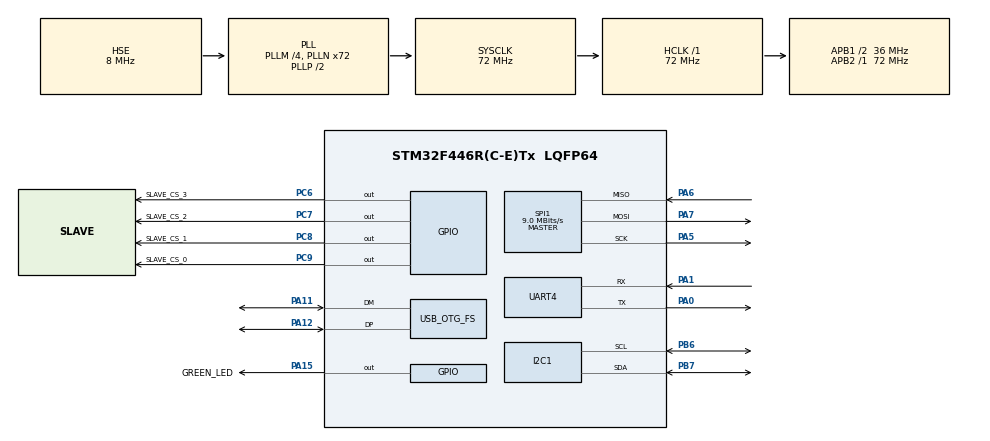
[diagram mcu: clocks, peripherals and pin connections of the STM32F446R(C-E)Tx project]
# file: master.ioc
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Dma.Request0=SPI1_RX
Dma.Request1=SPI1_TX
Dma.SPI1_RX.0.Direction=DMA_PERIPH_TO_MEMORY
Dma.SPI1_RX.0.FIFOMode=DMA_FIFOMODE_DISABLE
Dma.SPI1_RX.0.Instance=DMA2_Stream0
Dma.SPI1_RX.0.MemDataAlignment=DMA_MDATAALIGN_BYTE
Dma.SPI1_RX.0.MemInc=DMA_MINC_ENABLE
Dma.SPI1_RX.0.Mode=DMA_NORMAL
Dma.SPI1_RX.0.PeriphDataAlignment=DMA_PDATAALIGN_BYTE
Dma.SPI1_RX.0.PeriphInc=DMA_PINC_DISABLE
Dma.SPI1_RX.0.Priority=DMA_PRIORITY_LOW
Dma.SPI1_TX.1.Direction=DMA_MEMORY_TO_PERIPH
Dma.SPI1_TX.1.FIFOMode=DMA_FIFOMODE_DISABLE
Dma.SPI1_TX.1.Instance=DMA2_Stream3
Dma.SPI1_TX.1.MemDataAlignment=DMA_MDATAALIGN_BYTE
Dma.SPI1_TX.1.MemInc=DMA_MINC_ENABLE
Dma.SPI1_TX.1.Mode=DMA_NORMAL
Dma.SPI1_TX.1.PeriphDataAlignment=DMA_PDATAALIGN_BYTE
Dma.SPI1_TX.1.PeriphInc=DMA_PINC_DISABLE
Dma.SPI1_TX.1.Priority=DMA_PRIORITY_LOW
I2C1.I2C_Mode=I2C_Fast
Mcu.Family=STM32F4
Mcu.Name=STM32F446R(C-E)Tx
Mcu.Package=LQFP64
NVIC.DMA2_Stream0_IRQn=true\:0\:0\:false\:false\:true\:false\:true\:true
NVIC.DMA2_Stream3_IRQn=true\:0\:0\:false\:false\:true\:false\:true\:true
NVIC.I2C1_EV_IRQn=true\:0\:0\:false\:false\:true\:true\:true\:true
NVIC.OTG_FS_IRQn=true\:0\:0\:false\:false\:true\:false\:true\:true
NVIC.PriorityGroup=NVIC_PRIORITYGROUP_4
NVIC.SPI1_IRQn=true\:0\:0\:false\:false\:true\:true\:true\:true
PA0-WKUP.Mode=Asynchronous
PA0-WKUP.Signal=UART4_TX
PA1.Mode=Asynchronous
PA1.Signal=UART4_RX
PA11.Mode=Device_Only
PA11.Signal=USB_OTG_FS_DM
PA12.Mode=Device_Only
PA12.Signal=USB_OTG_FS_DP
PA13.Mode=Serial_Wire
PA13.Signal=SYS_JTMS-SWDIO
PA14.Mode=Serial_Wire
PA14.Signal=SYS_JTCK-SWCLK
PA15.GPIO_Label=GREEN_LED
PA15.Signal=GPIO_Output
PA5.Mode=Full_Duplex_Master
PA5.Signal=SPI1_SCK
PA6.Mode=Full_Duplex_Master
PA6.Signal=SPI1_MISO
PA7.Mode=Full_Duplex_Master
PA7.Signal=SPI1_MOSI
PB6.Mode=I2C
PB6.Signal=I2C1_SCL
PB7.Mode=I2C
PB7.Signal=I2C1_SDA
PC6.GPIO_Label=SLAVE_CS_3
PC6.Signal=GPIO_Output
PC7.GPIO_Label=SLAVE_CS_2
PC7.Signal=GPIO_Output
PC8.GPIO_Label=SLAVE_CS_1
PC8.Signal=GPIO_Output
PC9.GPIO_Label=SLAVE_CS_0
PC9.Signal=GPIO_Output
PH0-OSC_IN.Mode=HSE-External-Oscillator
PH0-OSC_IN.Signal=RCC_OSC_IN
PH1-OSC_OUT.Mode=HSE-External-Oscillator
PH1-OSC_OUT.Signal=RCC_OSC_OUT
ProjectManager.HeapSize=0x200
ProjectManager.StackSize=0x400
ProjectManager.TargetToolchain=STM32CubeIDE
RCC.AHBFreq_Value=72000000
RCC.APB1CLKDivider=RCC_HCLK_DIV2
RCC.APB1Freq_Value=36000000
RCC.APB1TimFreq_Value=72000000
RCC.APB2Freq_Value=72000000
RCC.APB2TimCLKDivider=1
RCC.APB2TimFreq_Value=72000000
RCC.CortexFreq_Value=72000000
RCC.HCLKFreq_Value=72000000
RCC.HSE_VALUE=8000000
RCC.PLLM=4
RCC.PLLN=72
RCC.PLLQ=3
RCC.SYSCLKFreq_VALUE=72000000
RCC.SYSCLKSource=RCC_SYSCLKSOURCE_PLLCLK
RCC.USBFreq_Value=48000000
RCC.VCOOutputFreq_Value=144000000
SPI1.BaudRatePrescaler=SPI_BAUDRATEPRESCALER_8
SPI1.CLKPhase=SPI_PHASE_1EDGE
SPI1.CLKPolarity=SPI_POLARITY_LOW
SPI1.CalculateBaudRate=9.0 MBits/s
SPI1.Direction=SPI_DIRECTION_2LINES
SPI1.Mode=SPI_MODE_MASTER
SPI1.VirtualType=VM_MASTER
UART4.VirtualMode=Asynchronous
USB_DEVICE.CLASS_NAME_FS=CDC
USB_DEVICE.VirtualMode-CDC_FS=Cdc
USB_DEVICE.VirtualModeFS=Cdc_FS
USB_OTG_FS.VirtualMode=Device_Only
VP_USB_DEVICE_VS_USB_DEVICE_CDC_FS.Mode=CDC_FS
board=custom

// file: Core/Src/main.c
/* USER CODE BEGIN Header */
/**
  ******************************************************************************
  * @file           : main.c
  * @brief          : Main program body
  ******************************************************************************
  * @attention
  *
  * Copyright (c) 2025 STMicroelectronics.
  * All rights reserved.
  *
  * This software is licensed under terms that can be found in the LICENSE file
  * in the root directory of this software component.
  * If no LICENSE file comes with this software, it is provided AS-IS.
  *
  ******************************************************************************
  */
/* USER CODE END Header */
#include "main.h"
#include "usb_device.h"

/* USER CODE BEGIN Includes */
#include "spi_master.h"
/* USER CODE END Includes */

I2C_HandleTypeDef hi2c1;

SPI_HandleTypeDef hspi1;
DMA_HandleTypeDef hdma_spi1_rx;
DMA_HandleTypeDef hdma_spi1_tx;

UART_HandleTypeDef huart4;

void SystemClock_Config(void);
static void MX_GPIO_Init(void);
static void MX_DMA_Init(void);
static void MX_I2C1_Init(void);
static void MX_SPI1_Init(void);
static void MX_UART4_Init(void);

int main(void)
{

  /* MCU Configuration--------------------------------------------------------*/

  /* Reset of all peripherals, Initializes the Flash interface and the Systick. */
  HAL_Init();

  /* Configure the system clock */
  SystemClock_Config();

  /* Initialize all configured peripherals */
  MX_GPIO_Init();
  MX_DMA_Init();
  MX_I2C1_Init();
  MX_SPI1_Init();
  MX_UART4_Init();
  MX_USB_DEVICE_Init();
  /* USER CODE BEGIN 2 */

  MotorMaster_Init(&hspi1, &huart4);
  usb_printf("USB Test/r/n");
  HAL_GPIO_WritePin(GREEN_LED_GPIO_Port, GREEN_LED_Pin, GPIO_PIN_SET);
  HAL_Delay(3000);
  HAL_GPIO_WritePin(GREEN_LED_GPIO_Port, GREEN_LED_Pin, GPIO_PIN_RESET);

  /* USER CODE END 2 */

  /* Infinite loop */
  while (1)
  {

    /* USER CODE BEGIN 3 */

	MotorMaster_ProcessLoop();
  }
  /* USER CODE END 3 */
}

void SystemClock_Config(void)
{
  RCC_OscInitTypeDef RCC_OscInitStruct = {0};
  RCC_ClkInitTypeDef RCC_ClkInitStruct = {0};

  /** Configure the main internal regulator output voltage
  */
  __HAL_RCC_PWR_CLK_ENABLE();
  __HAL_PWR_VOLTAGESCALING_CONFIG(PWR_REGULATOR_VOLTAGE_SCALE3);

  /** Initializes the RCC Oscillators according to the specified parameters
  * in the RCC_OscInitTypeDef structure.
  */
  RCC_OscInitStruct.OscillatorType = RCC_OSCILLATORTYPE_HSE;
  RCC_OscInitStruct.HSEState = RCC_HSE_ON;
  RCC_OscInitStruct.PLL.PLLState = RCC_PLL_ON;
  RCC_OscInitStruct.PLL.PLLSource = RCC_PLLSOURCE_HSE;
  RCC_OscInitStruct.PLL.PLLM = 4;
  RCC_OscInitStruct.PLL.PLLN = 72;
  RCC_OscInitStruct.PLL.PLLP = RCC_PLLP_DIV2;
  RCC_OscInitStruct.PLL.PLLQ = 3;
  RCC_OscInitStruct.PLL.PLLR = 2;
  if (HAL_RCC_OscConfig(&RCC_OscInitStruct) != HAL_OK)
  {
    Error_Handler();
  }

  /** Initializes the CPU, AHB and APB buses clocks
  */
  RCC_ClkInitStruct.ClockType = RCC_CLOCKTYPE_HCLK|RCC_CLOCKTYPE_SYSCLK
                              |RCC_CLOCKTYPE_PCLK1|RCC_CLOCKTYPE_PCLK2;
  RCC_ClkInitStruct.SYSCLKSource = RCC_SYSCLKSOURCE_PLLCLK;
  RCC_ClkInitStruct.AHBCLKDivider = RCC_SYSCLK_DIV1;
  RCC_ClkInitStruct.APB1CLKDivider = RCC_HCLK_DIV2;
  RCC_ClkInitStruct.APB2CLKDivider = RCC_HCLK_DIV1;

  if (HAL_RCC_ClockConfig(&RCC_ClkInitStruct, FLASH_LATENCY_2) != HAL_OK)
  {
    Error_Handler();
  }
}

static void MX_I2C1_Init(void)
{

  hi2c1.Instance = I2C1;
  hi2c1.Init.ClockSpeed = 100000;
  hi2c1.Init.DutyCycle = I2C_DUTYCYCLE_2;
  hi2c1.Init.OwnAddress1 = 0;
  hi2c1.Init.AddressingMode = I2C_ADDRESSINGMODE_7BIT;
  hi2c1.Init.DualAddressMode = I2C_DUALADDRESS_DISABLE;
  hi2c1.Init.OwnAddress2 = 0;
  hi2c1.Init.GeneralCallMode = I2C_GENERALCALL_DISABLE;
  hi2c1.Init.NoStretchMode = I2C_NOSTRETCH_DISABLE;
  if (HAL_I2C_Init(&hi2c1) != HAL_OK)
  {
    Error_Handler();
  }

}

static void MX_SPI1_Init(void)
{

  /* SPI1 parameter configuration*/
  hspi1.Instance = SPI1;
  hspi1.Init.Mode = SPI_MODE_MASTER;
  hspi1.Init.Direction = SPI_DIRECTION_2LINES;
  hspi1.Init.DataSize = SPI_DATASIZE_8BIT;
  hspi1.Init.CLKPolarity = SPI_POLARITY_LOW;
  hspi1.Init.CLKPhase = SPI_PHASE_1EDGE;
  hspi1.Init.NSS = SPI_NSS_SOFT;
  hspi1.Init.BaudRatePrescaler = SPI_BAUDRATEPRESCALER_64;
  hspi1.Init.FirstBit = SPI_FIRSTBIT_MSB;
  hspi1.Init.TIMode = SPI_TIMODE_DISABLE;
  hspi1.Init.CRCCalculation = SPI_CRCCALCULATION_DISABLE;
  hspi1.Init.CRCPolynomial = 10;
  if (HAL_SPI_Init(&hspi1) != HAL_OK)
  {
    Error_Handler();
  }

}

static void MX_UART4_Init(void)
{

  huart4.Instance = UART4;
  huart4.Init.BaudRate = 115200;
  huart4.Init.WordLength = UART_WORDLENGTH_8B;
  huart4.Init.StopBits = UART_STOPBITS_1;
  huart4.Init.Parity = UART_PARITY_NONE;
  huart4.Init.Mode = UART_MODE_TX_RX;
  huart4.Init.HwFlowCtl = UART_HWCONTROL_NONE;
  huart4.Init.OverSampling = UART_OVERSAMPLING_16;
  if (HAL_UART_Init(&huart4) != HAL_OK)
  {
    Error_Handler();
  }

}

static void MX_DMA_Init(void)
{

  /* DMA controller clock enable */
  __HAL_RCC_DMA2_CLK_ENABLE();

  /* DMA interrupt init */
  /* DMA2_Stream0_IRQn interrupt configuration */
  HAL_NVIC_SetPriority(DMA2_Stream0_IRQn, 0, 0);
  HAL_NVIC_EnableIRQ(DMA2_Stream0_IRQn);
  /* DMA2_Stream3_IRQn interrupt configuration */
  HAL_NVIC_SetPriority(DMA2_Stream3_IRQn, 0, 0);
  HAL_NVIC_EnableIRQ(DMA2_Stream3_IRQn);

}

static void MX_GPIO_Init(void)
{
  GPIO_InitTypeDef GPIO_InitStruct = {0};

  /* GPIO Ports Clock Enable */
  __HAL_RCC_GPIOH_CLK_ENABLE();
  __HAL_RCC_GPIOA_CLK_ENABLE();
  __HAL_RCC_GPIOC_CLK_ENABLE();
  __HAL_RCC_GPIOB_CLK_ENABLE();

  /*Configure GPIO pin Output Level */
  HAL_GPIO_WritePin(GPIOC, SLAVE_CS_3_Pin|SLAVE_CS_2_Pin|SLAVE_CS_1_Pin|SLAVE_CS_0_Pin, GPIO_PIN_RESET);

  /*Configure GPIO pin Output Level */
  HAL_GPIO_WritePin(GREEN_LED_GPIO_Port, GREEN_LED_Pin, GPIO_PIN_RESET);

  /*Configure GPIO pins : SLAVE_CS_3_Pin SLAVE_CS_2_Pin SLAVE_CS_1_Pin SLAVE_CS_0_Pin */
  GPIO_InitStruct.Pin = SLAVE_CS_3_Pin|SLAVE_CS_2_Pin|SLAVE_CS_1_Pin|SLAVE_CS_0_Pin;
  GPIO_InitStruct.Mode = GPIO_MODE_OUTPUT_PP;
  GPIO_InitStruct.Pull = GPIO_NOPULL;
  GPIO_InitStruct.Speed = GPIO_SPEED_FREQ_LOW;
  HAL_GPIO_Init(GPIOC, &GPIO_InitStruct);

  /*Configure GPIO pin : GREEN_LED_Pin */
  GPIO_InitStruct.Pin = GREEN_LED_Pin;
  GPIO_InitStruct.Mode = GPIO_MODE_OUTPUT_PP;
  GPIO_InitStruct.Pull = GPIO_NOPULL;
  GPIO_InitStruct.Speed = GPIO_SPEED_FREQ_LOW;
  HAL_GPIO_Init(GREEN_LED_GPIO_Port, &GPIO_InitStruct);

}

void Error_Handler(void)
{
  __disable_irq();
  while (1)
  {
  }
}
